# K1921VK035 register map
Vendor: NIIET; Series: K1921VKx; File version: 2.10
CPU: CM4 r0p1, little endian, MPU, FPU, 3 interrupt priority bits
Registers are 32-bit, read-write, reset 0x0 unless marked. A register's access mark holds for its fields unless they carry their own. Offsets are from the block's base; [hi:lo] are bit positions; lines under a group give offsets from that group; {n}, {i} and the like mark numbered series; 'fields as' and 'values as' point back to an identical list.

## ADC — ADC control registers
Base 0x40000000
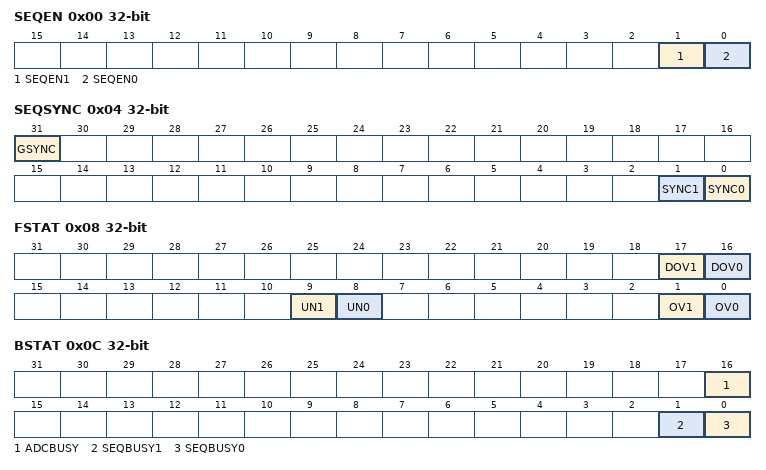
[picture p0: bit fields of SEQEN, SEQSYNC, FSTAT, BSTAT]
0x00 SEQEN — Enable sequencer register
  [1] SEQEN1 — Enable sequencer 1
  [0] SEQEN0 — Enable sequencer 0
0x04 SEQSYNC — Sequencer sync register
  [31] GSYNC wo — Sync all sequencers
  [1] SYNC1 — Enable sequencer 1 software sync
  [0] SYNC0 — Enable sequencer 0 software sync
0x08 FSTAT — FIFO overflow status register
  [17] DOV1 — Sequencer 1 FIFO DMA request overflow
  [16] DOV0 — Sequencer 0 FIFO DMA request overflow
  [9] UN1 — Sequencer 1 FIFO underflow
  [8] UN0 — Sequencer 0 FIFO underflow
  [1] OV1 — Sequencer 1 FIFO overflow
  [0] OV0 — Sequencer 0 FIFO overflow
0x0C BSTAT ro — Busy status register
  [16] ADCBUSY — ADC module conversion busy
  [1] SEQBUSY1 — Sequencer 1 busy
  [0] SEQBUSY0 — Sequencer 0 busy
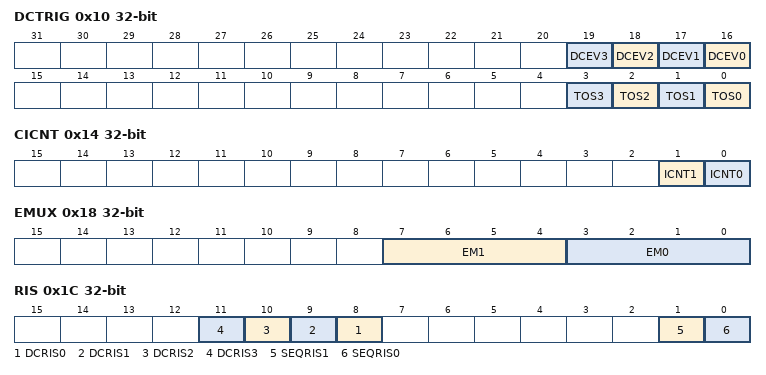
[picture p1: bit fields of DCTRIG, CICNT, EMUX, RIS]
0x10 DCTRIG — Digital comparator output trigger status register
  [n+16] DCEV{n} (n=0..3) — Digital compare event {n}
  [n] TOS{n} (n=0..3) — DC {n} output trigger status
0x14 CICNT — Interrupt counter clear control
  [1] ICNT1 — Clear interrupt counter on sequencer 1 start
  [0] ICNT0 — Clear interrupt counter on sequencer 0 start
0x18 EMUX — Sequencer start event selection register
  [7:4] EM1 — Select start event for sequencer 1
    0=SwReq (software request by GSYNC bit); 1=GPIOA (GPIOA interrupt); 2=GPIOB (GPIOB interrupt); {v}=TMR{v-3} (Timer {v-3} request) (v=3..6); 7=PWM012A (PWM0,1,2 A channel request); 8=PWM012B (PWM0,1,2 B channel request); 15=Cycle mode
  [3:0] EM0 — Select start event for sequencer 0
    values as EM1
0x1C RIS ro — Raw interrupt status register
  [n+8] DCRIS{n} (n=0..3) — Raw interrupt status of Digital Comparator {n}
  [1] SEQRIS1 — Sequencer 1 raw interrupt status
  [0] SEQRIS0 — Sequencer 0 raw interrupt status
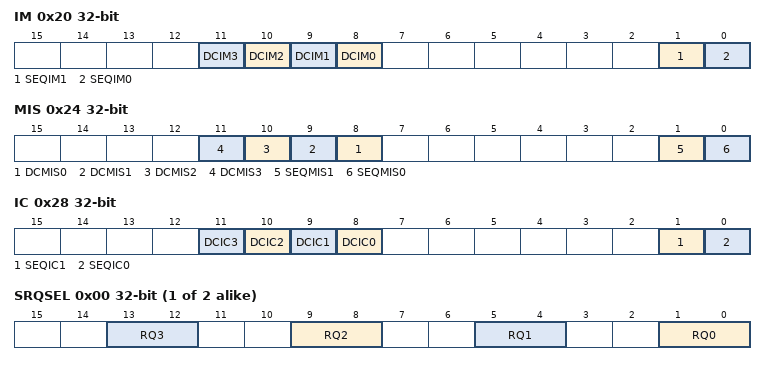
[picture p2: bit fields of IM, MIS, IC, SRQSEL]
0x20 IM — Interrupt mask register
  [n+8] DCIM{n} (n=0..3) — Interrupt mask of Digital Comparator {n}
  [1] SEQIM1 — Sequencer 1 interrupt mask
  [0] SEQIM0 — Sequencer 0 interrupt mask
0x24 MIS ro — Masked interrupt status and clear register
  [n+8] DCMIS{n} (n=0..3) — DC {n} masked interrupt status
  [1] SEQMIS1 — Sequencer 1 masked interrupt status
  [0] SEQMIS0 — Sequencer 0 masked interrupt status
0x28 IC wo — Interrupt clear register
  [n+8] DCIC{n} (n=0..3) — DC {n} interrupt status clear
  [1] SEQIC1 — Sequencer 1 interrupt status clear
  [0] SEQIC0 — Sequencer 0 interrupt status clear
{0x40+0x34*i} SEQ[{i}] (i=0..1) group
  0x00 SRQSEL — Sequencer request ADC channels selection register
    [4n+1:4n] RQ{n} (n=0..3) — Select ADC channel for request {n}
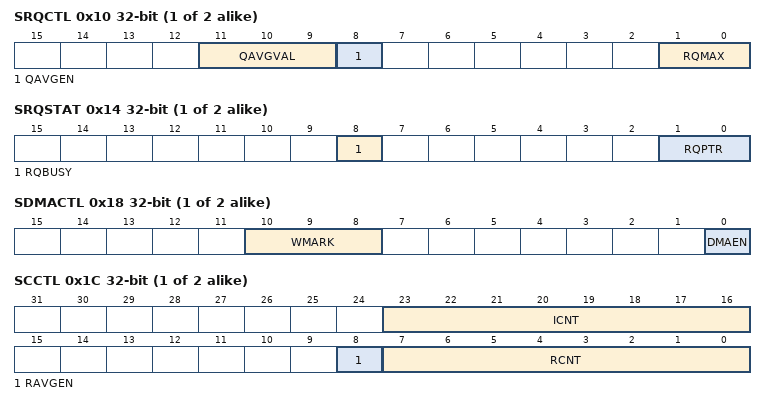
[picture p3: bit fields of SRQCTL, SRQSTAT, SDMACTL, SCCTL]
  0x10 SRQCTL — Sequencer request control register
    [11:9] QAVGVAL — Queue average value
      0=Disable (Average disabled); 1=Average2 (Average with 2 measures); 2=Average4 (Average with 4 measures); 3=Average8 (Average with 8 measures); 4=Average16 (Average with 16 measures); 5=Average32 (Average with 32 measures); 6=Average64 (Average with 64 measures)
    [8] QAVGEN — Queue avearage (scanning) enable
    [1:0] RQMAX — Request queue max depth
  0x14 SRQSTAT ro — Sequencer request status register
    [8] RQBUSY — Active request status
    [1:0] RQPTR — Pointer to queue current request
  0x18 SDMACTL — Sequencer DMA control register
    [10:8] WMARK — FIFO load threshold for DMA request generation
      1=Level1 (1 measure for dma request); 2=Level2 (2 measures for dma request); 3=Level4 (4 measures for dma request); 4=Level8 (8 measures for dma request); 5=Level16 (16 measures for dma request); 6=Level32 (32 measures for dma request)
    [0] DMAEN — Enable DMA use
  0x1C SCCTL — Sequencer ADC interrupt and restart counter control register
    [23:16] ICNT — Number of ADC requests for interrupt generation
    [8] RAVGEN — Average of ADC restarts enable
    [7:0] RCNT — Current number of ADC restarts by sequencer
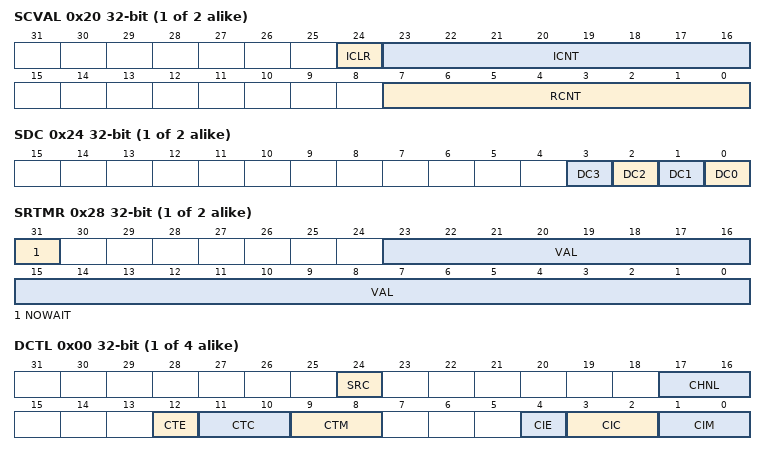
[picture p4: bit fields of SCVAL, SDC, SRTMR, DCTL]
  0x20 SCVAL wo — Sequencer ADC interrupt and restart counter current value register
    [24] ICLR — Clear interrupt counter
    [23:16] ICNT ro — Current number of ADC requests for interrupt generation
    [7:0] RCNT ro — Current number of ADC restarts by sequencer
  0x24 SDC — Sequencer digital comparator selection register
    [n] DC{n} (n=0..3) — Enable DC {n}
  0x28 SRTMR — Sequencer ADC restart timer register
    [31] NOWAIT — Timer update with no waiting the end of current seq task
    [23:0] VAL — Sequencer ADC restart timer value
  0x2C SFLOAD ro — Sequencer FIFO load status register
    [5:0] VAL — Sequencer FIFO current load value
  0x30 SFIFO ro — Sequencer FIFO register
    [11:0] DATA — AD conversion value
{0x200+0xC*i} DC[{i}] (i=0..3) group
  0x00 DCTL — Digital comparator control register
    [24] SRC — Select data source for comparation: ADC module (0) or sequencer(1)
    [17:16] CHNL — ADC channel selection
    [12] CTE — Enable DC output trigger
    [11:10] CTC — DC output trigger compare conditions
      0=Low (result lower or equal COMP0); 1=Window (result between COMP0 and COMP1 or equal any of them); 2=High (result higher or equal COMP1)
    [9:8] CTM — DC output trigger mode
      0=multiple trigger mode; 1=single trigger mode; 2=MultipleHyst (multiple trigger mode with hysteresis); 3=SingleHyst (single trigger mode with hysteresis)
    [4] CIE — Enable DC interrupt generation
    [3:2] CIC — DC interrupt generation compare conditions
      values as CTC
    [1:0] CIM — DC interrupt generation mode
      values as CTM
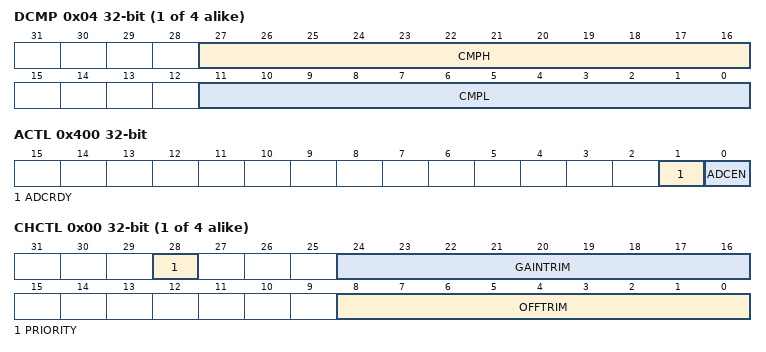
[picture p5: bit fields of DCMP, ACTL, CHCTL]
  0x04 DCMP — Digital comparator range register
    [27:16] CMPH — High threshold compare value
    [11:0] CMPL — Low threshold compare value
  0x08 DDATA ro — Digital comparator last compared data register
    [11:0] VAL — Value of last compared AD conversion result
0x400 ACTL — ADC module control register
  [1] ADCRDY ro — ADC ready for conversions
  [0] ADCEN — Enable ADC module
{0x500+4i} CHCTL[{i}] (i=0..3) group
  0x00 CHCTL — ADC channel control register
    [28] PRIORITY — ADC channel priority level
    [24:16] GAINTRIM — ADC channel gain trimm value
    [8:0] OFFTRIM — ADC channel offset trimm value
